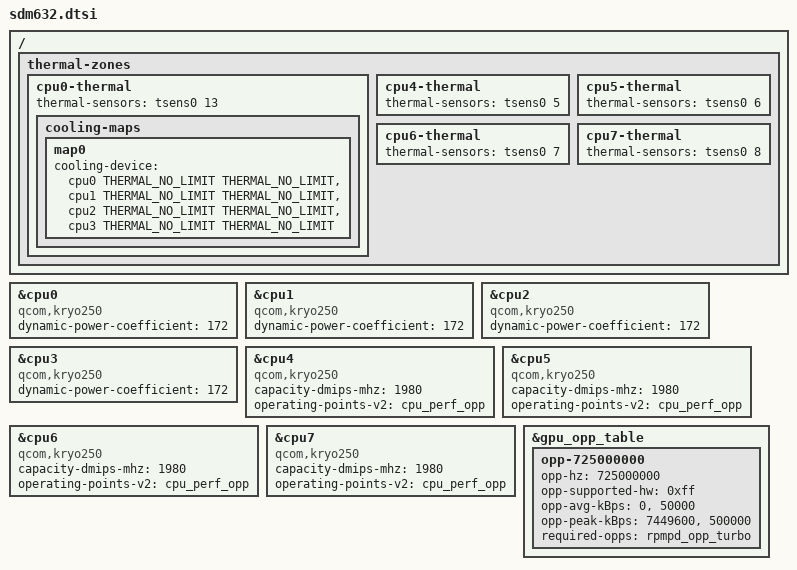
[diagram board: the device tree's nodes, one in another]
// SPDX-License-Identifier: BSD-3-Clause
/* Copyright (c) 2022, The Linux Foundation. All rights reserved. */

#include "msm8953.dtsi"

/ {
	thermal-zones {
		/delete-node/cpu1-thermal;
		/delete-node/cpu2-thermal;
		/delete-node/cpu3-thermal;

		cpu0-thermal {
			thermal-sensors = <&tsens0 13>;

			cooling-maps {
				map0 {
					cooling-device = <&cpu0 THERMAL_NO_LIMIT THERMAL_NO_LIMIT>,
							 <&cpu1 THERMAL_NO_LIMIT THERMAL_NO_LIMIT>,
							 <&cpu2 THERMAL_NO_LIMIT THERMAL_NO_LIMIT>,
							 <&cpu3 THERMAL_NO_LIMIT THERMAL_NO_LIMIT>;
				};
			};
		};

		cpu4-thermal {
			thermal-sensors = <&tsens0 5>;
		};

		cpu5-thermal {
			thermal-sensors = <&tsens0 6>;
		};

		cpu6-thermal {
			thermal-sensors = <&tsens0 7>;
		};

		cpu7-thermal {
			thermal-sensors = <&tsens0 8>;
		};
	};
};

/*
 * SDM632 uses Kryo 250 instead of Cortex A53
 * cpu0-3 are efficiency cores, cpu4-7 are performance cores
 */
&cpu0 {
	compatible = "qcom,kryo250";
	dynamic-power-coefficient = <172>;
};

&cpu1 {
	compatible = "qcom,kryo250";
	dynamic-power-coefficient = <172>;
};

&cpu2 {
	compatible = "qcom,kryo250";
	dynamic-power-coefficient = <172>;
};

&cpu3 {
	compatible = "qcom,kryo250";
	dynamic-power-coefficient = <172>;
};

&cpu4 {
	compatible = "qcom,kryo250";
	capacity-dmips-mhz = <1980>;
	operating-points-v2 = <&cpu_perf_opp>;
};

&cpu5 {
	compatible = "qcom,kryo250";
	capacity-dmips-mhz = <1980>;
	operating-points-v2 = <&cpu_perf_opp>;
};

&cpu6 {
	compatible = "qcom,kryo250";
	capacity-dmips-mhz = <1980>;
	operating-points-v2 = <&cpu_perf_opp>;
};

&cpu7 {
	compatible = "qcom,kryo250";
	capacity-dmips-mhz = <1980>;
	operating-points-v2 = <&cpu_perf_opp>;
};

&gpu_opp_table {
	opp-725000000 {
		opp-hz = /bits/ 64 <725000000>;
		opp-supported-hw = <0xff>;
		opp-avg-kBps = <0>, <50000>;
		opp-peak-kBps = <7449600>, <500000>;
		required-opps = <&rpmpd_opp_turbo>;
	};
};
